# cslr_i2cc55x_001 register map
Vendor: Texas Instruments
Peripheral module from a debugger description file.
Registers are 16-bit, read-write, reset 0x0 unless marked. A register's access mark holds for its fields unless they carry their own. Offsets are as the file gives them; lines under a group give offsets from that group; [hi:lo] are bit positions; {n}, {i} and the like mark numbered series; 'fields as' and 'values as' point back to an identical list; <NAME> marks a mode.

## I2C — Inter-Integrated Circuit
0x00 I2CMDR2 32-bit access per field — I2C Mode Register 2
  [0] IDLEEN rw — I2C idle enable bit
    0=The I2C does not go into an IDLE state when the DSP executes the IDLE instruction; 1=The I2C does go into an IDLE state when the DSP executes the IDLE instruction
0x00 I2COAR — I2C Own Address Register
  [9:0] OAR — In 7-bit addressing mode (XA = 0 in I2CMDR): Bits 6-0 provide the 7-bit slave address of the I2C module. In 10-bit addressing mode (XA = 1 in I2CMDR): Bits 9-0 provide the 10-bit slave address of the I2C module.
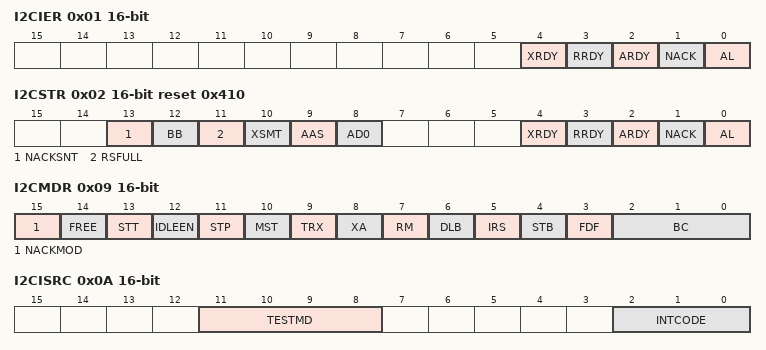
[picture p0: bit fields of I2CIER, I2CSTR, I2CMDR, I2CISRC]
0x01 I2CIER access per field — I2C Interrupt Enable Register
  [all] fields
    0=Interrupt request disabled; 1=Interrupt request enabled
  [4] XRDY rw — Transmit-data-ready interrupt enable bit
  [3] RRDY rw — Receive-data-ready interrupt enable bit
  [2] ARDY rw — Register-access-ready interrupt enable bit
  [1] NACK rw — No-acknowledgement interrupt enable bit
  [0] AL rw — Arbitration-lost interrupt enable bit
0x02 I2CSTR access not given reset 0x410 — I2C Status Register
  [13] NACKSNT — NACK sent bit (not available in TMS320VC5503/5507/5509 DSPs). (access RW1C)
    0=NACK not sent; 1=NACK sent
  [12] BB — Bus busy bit. (access RW1C)
    0=Bus free; 1=Bus busy
  [11] RSFULL ro — Receive shift register full bit.
    0=No overrun detected; 1=Overrun detected
  [10] XSMT ro — Transmit shift register empty bit.
    0=Underflow detected (empty); 1=No underflow detected (not empty)
  [9] AAS ro — Addressed-as-slave bit
    0=In the 7-bit addressing mode, the AAS bit is cleared when receiving a NACK, a STOP condition, or a repeated START condition; 1=The I2C module has recognized its own slave address or an address of all zeros (general call)
  [8] AD0 ro — Address 0 bit
    0=AD0 has been cleared by a START or STOP condition; 1=An address of all zeros (general call) is detected
  [4] XRDY — Transmit-data-ready interrupt flag bit. (access RW1C)
    0=I2CDXR not ready; 1=I2CDXR ready:
  [3] RRDY — Receive-data-ready interrupt flag bit. (access RW1C)
    0=I2CDRR not ready; 1=I2CDRR ready:
  [2] ARDY — Register-access-ready interrupt flag bit (only applicable when the I2C module is in the master mode). (access RW1C)
    0=The registers are not ready to be accessed; 1=The registers are ready to be accessed
  [1] NACK — No-acknowledgement interrupt flag bit. (access RW1C)
    0=ACK received/NACK not received; 1=NACK bit received
  [0] AL — Arbitration-lost interrupt flag bit (only applicable when the I2C module is a master-transmitter). (access RW1C)
    0=Arbitration not lost; 1=Arbitration lost
0x03 I2CCLKL — I2C Clock Divider Registers
  [15:0] ICCL — Clock low-time divide-down value of 1-65536.
0x04 I2CCLKH — I2C Clock Divider Registers
  [15:0] ICCH — Clock high-time divide-down value of 1-65536.
0x05 I2CCNT — I2C Data Count Register
  [15:0] ICDC — Data count value.
0x06 I2CDRR ro — I2C Data Receive Register
  [7:0] DATA — Receive data
0x07 I2CSAR ro (reset mask 0xFC00) — I2C Slave Address Register
  [9:0] SAR — In 7-bit addressing mode (XA = 0 in I2CMDR): Bits 6-0 provide the 7-bit slave address that the I2C module transmits when it is in the master-transmitter mode. In 10-bit addressing mode (XA = 1 in I2CMDR): Bits 9-0 provide the 10-bit slave address that the I2C module transmits when it is in the master-transmitter mode.
0x08 I2CDXR access per field reset 0x8 — I2C Data Transmit Register
  [7:0] DATA rw — Transmit data
0x09 I2CMDR — I2C Mode Register
  [15] NACKMOD — NACK mode bit (not available in TMS320VC5503/5507/5509 DSPs).
    0=The I2C module sends an acknowledge (ACK) bit to the transmitter during the each acknowledge cycle on the bus; 0=The I2C module sends an ACK bit during each acknowledge cycle until the internal data counter counts down to 0; 1=The I2C module sends a NACK bit to the transmitter during the next acknowledge cycle on the bus
  [14] FREE — This emulation mode bit is used to determine what the state of the I2C module will be when a breakpoint is encountered in the high-level language debugger.
    0=If SCL is low when the breakpoint occurs, the I2C module stops immediately and keeps driving SCL low, whether the I2C module is the transmitter or the receiver; 0=A breakpoint forces the I2C module to stop when the current transmission/reception is complete; 1=The I2C module runs free
  [13] STT — START condition bit (only applicable when the I2C module is a master).
    0=In the master mode, STT is automatically cleared after the START condition has been generated; 1=In the master mode, setting STT to 1 causes the I2C module to generate a START condition on the I2C-bus; 0=In the slave mode, if STT is 0, the I2C module does not monitor the bus for commands from a master; 1=In the slave mode, if STT is 1, the I2C module monitors the bus and transmits/receives data in response to commands from a master
  [12] IDLEEN — Idle enable bit
    0=The I2C module cannot be affected when the CPU executes an IDLE instruction; 1=Setting this bit allows the I2C module to be deactivated by an IDLE instruction
  [11] STP — STOP condition bit (only applicable when the I2C module is a master).
    0=STP is automatically cleared after the STOP condition has been generated; 1=STP has been set by the DSP to generate a STOP condition when the internal data counter of the I2C module counts down to 0
  [10] MST — Master mode bit.
    0=Slave mode; 1=Master mode
  [9] TRX — Transmitter mode bit.
    0=Receiver mode; 1=Transmitter mode
  [8] XA — Expanded address enable bit.
    0=7-bit addressing mode (normal address mode); 1=10-bit addressing mode (expanded address mode)
  [7] RM — Repeat mode bit (only applicable when the I2C module is a master-transmitter).
    0=Nonrepeat mode; 1=Repeat mode
  [6] DLB — Digital loopback mode bit.
    0=Digital loopback mode is disabled; 1=Digital loopback mode is enabled
  [5] IRS — I2C module reset bit.
    0=The I2C module is in reset/disabled; 1=The I2C module is enabled
  [4] STB — START byte mode bit.
    0=The I2C module is not in the START byte mode; 1=The I2C module is in the START byte mode
  [3] FDF — Free data format mode bit.
    0=Free data format mode is disabled; 1=Free data format mode is enabled
  [2:0] BC — Bit count bits.
    0=8 bits per data byte; 1=1 bit per data byte; {v}={v} bits per data byte (v=2..7)
0x0A I2CISRC access per field — I2C Interrupt Source Register
  [11:8] TESTMD rw — Although there is no reason for you to write to I2CISRC, remember that bits 11-8 must remain 0 for proper operation of the I2C module.
  [2:0] INTCODE ro — Interrupt code bits.
    0=None; 1=Arbitration lost; 2=No-acknowledgement condition detected; 3=Registers ready to be accessed; 4=Receive data ready; 5=Transmit data ready
0x0C I2CPSC access per field — I2C Prescaler Register
  [7:0] IPSC rw — I2C prescaler divide-down value.
